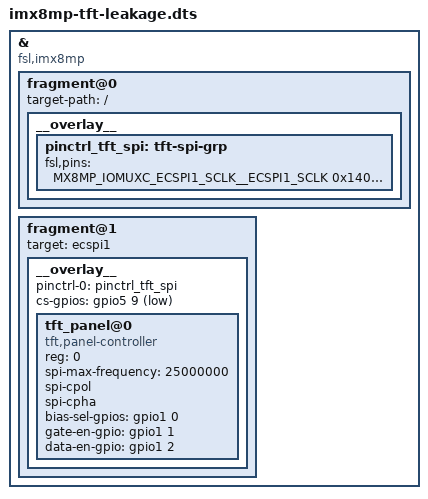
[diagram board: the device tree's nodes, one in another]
// SPDX-License-Identifier: (GPL-2.0+ OR MIT)
/*
 * Copyright 2026 TFT Leakage Reduction Project
 *
 * Device Tree Overlay for TFT Panel Controller
 * Target: i.MX8MP with ECSPI1
 */

/dts-v1/;
/plugin/;

#include <dt-bindings/gpio/gpio.h>
#include <dt-bindings/clock/imx8mp-clock.h>

& {
    compatible = "fsl,imx8mp";

    fragment@0 {
        target-path = "/";
        __overlay__ {
            pinctrl_tft_spi: tft-spi-grp {
                fsl,pins = <
                    /* ECSPI1 SCLK - GPIO5_IO6 */
                    MX8MP_IOMUXC_ECSPI1_SCLK__ECSPI1_SCLK 0x140
                    /* ECSPI1 MOSI - GPIO5_IO8 */
                    MX8MP_IOMUXC_ECSPI1_MOSI__ECSPI1_MOSI 0x140
                    /* ECSPI1 MISO - GPIO5_IO7 */
                    MX8MP_IOMUXC_ECSPI1_MISO__ECSPI1_MISO 0x140
                    /* ECSPI1 SS0 - GPIO5_IO9 */
                    MX8MP_IOMUXC_ECSPI1_SS0__GPIO5_IO09   0x140
                >;
            };
        };
    };

    fragment@1 {
        target = <&ecspi1>;
        __overlay__ {
            #address-cells = <1>;
            #size-cells = <0>;
            pinctrl-names = "default";
            pinctrl-0 = <&pinctrl_tft_spi>;
            cs-gpios = <&gpio5 9 GPIO_ACTIVE_LOW>;
            status = "okay";

            /* TFT Panel Controller */
            tft_panel@0 {
                compatible = "tft,panel-controller";
                reg = <0>;
                spi-max-frequency = <25000000>; /* 25 MHz */
                spi-cpol;
                spi-cpha;

                /* Panel control GPIOs (optional) */
                bias-sel-gpios = <&gpio1 0 0>;  /* BIAS_SEL[2:0] */
                gate-en-gpio = <&gpio1 1 0>;
                data-en-gpio = <&gpio1 2 0>;
            };
        };
    };
};
